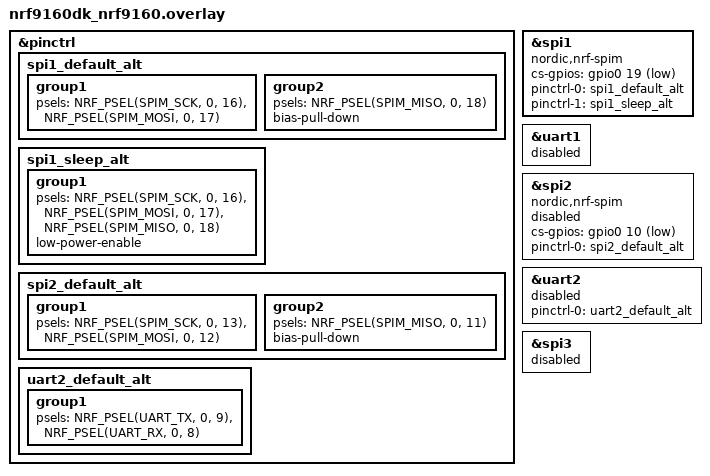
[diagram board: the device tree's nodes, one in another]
&pinctrl {
	spi1_default_alt: spi1_default_alt {
		group1 {
			psels = <NRF_PSEL(SPIM_SCK, 0, 16)>,
				<NRF_PSEL(SPIM_MOSI, 0, 17)>;
		};
		group2 {
			psels = <NRF_PSEL(SPIM_MISO, 0, 18)>;
			bias-pull-down;
		};
	};

	spi1_sleep_alt: spi1_sleep_alt {
		group1 {
			psels = <NRF_PSEL(SPIM_SCK, 0, 16)>,
				<NRF_PSEL(SPIM_MOSI, 0, 17)>,
				<NRF_PSEL(SPIM_MISO, 0, 18)>;
			low-power-enable;
		};
	};

	spi2_default_alt: spi2_default_alt {
		group1 {
			psels = <NRF_PSEL(SPIM_SCK, 0, 13)>,
				<NRF_PSEL(SPIM_MOSI, 0, 12)>;
		};
		group2 {
			psels = <NRF_PSEL(SPIM_MISO, 0, 11)>;
			bias-pull-down;
		};
	};

	uart2_default_alt: uart2_default_alt {
		group1 {
			psels = <NRF_PSEL(UART_TX, 0, 9)>,
				<NRF_PSEL(UART_RX, 0, 8)>;
		};
	};
};

/* This node corresponds to the SPIM1 peripheral that is to be used via
 * the Zephyr driver, so it must have the status set to "okay".
 */
&spi1 {
	compatible = "nordic,nrf-spim";
	status = "okay";
	cs-gpios = <&gpio0 19 GPIO_ACTIVE_LOW>;
	pinctrl-0 = <&spi1_default_alt>;
	pinctrl-1 = <&spi1_sleep_alt>;
	pinctrl-names = "default", "sleep";
};

/* The UARTE1 peripheral share the same ID with SPIM1, hence these two
 * peripherals cannot be used simultaneously and this node must be disabled.
 */
&uart1 {
	status = "disabled";
};

/* The following two nodes (corresponding to the SPIM2 and UARTE2 peripherals,
 * respectively) need to be disabled so that Zephyr drivers won't initialize
 * those instances; the application will use them via nrfx drivers. But their
 * pins must be specified, as the application expects to get this information
 * from devicetree.
 */
&spi2 {
	compatible = "nordic,nrf-spim";
	status = "disabled";
	cs-gpios = <&gpio0 10 GPIO_ACTIVE_LOW>;
	pinctrl-0 = <&spi2_default_alt>;
	/delete-property/ pinctrl-1;
	pinctrl-names = "default";
};

&uart2 {
	status = "disabled";
	pinctrl-0 = <&uart2_default_alt>;
	/delete-property/ pinctrl-1;
	pinctrl-names = "default";
};

/* This node also needs to be disabled, as in the default nrf9160dk_nrf9160
 * board configuration it uses the same pin numbers that are above assigned
 * to the spi1 node (17, 18, and 19).
 */
&spi3 {
	status = "disabled";
};
